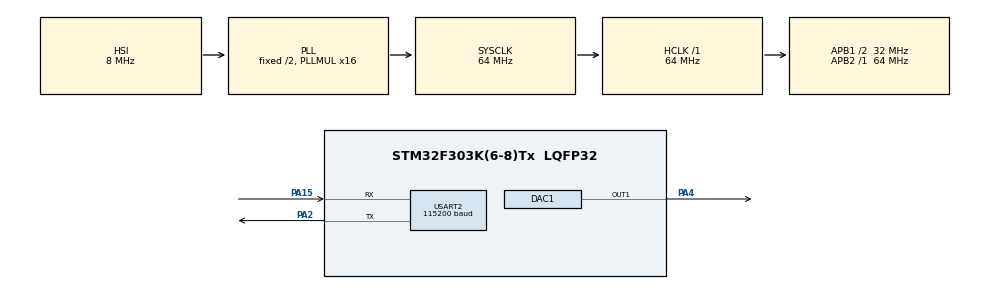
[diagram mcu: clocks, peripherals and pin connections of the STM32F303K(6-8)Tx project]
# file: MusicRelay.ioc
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Mcu.Family=STM32F3
RCC.CortexFreq_Value=64000000
RCC.SYSCLKSourceVirtual=RCC_SYSCLKSOURCE_PLLCLK
NVIC.TIM7_DAC2_IRQn=true\:0\:0\:false\:false\:true\:true\:true
RCC.APB1CLKDivider=RCC_HCLK_DIV2
NVIC.USART2_IRQn=true\:0\:0\:false\:false\:true\:true\:true
USART2.BaudRate=115200
ProjectManager.StackSize=0x400
VP_TIM7_VS_ClockSourceINT.Mode=Enable_Timer
ProjectManager.TargetToolchain=STM32CubeIDE
SH.COMP_DAC11_group.0=DAC1_OUT1,DAC_OUT1
RCC.HCLKFreq_Value=64000000
RCC.APB2TimFreq_Value=64000000
TIM7.Period=160-1
RCC.AHBFreq_Value=64000000
RCC.HSE_VALUE=8000000
TIM7.Prescaler=10-1
board=custom
USART2.VirtualMode-Asynchronous=VM_ASYNC
PA15.Mode=Asynchronous
RCC.PLLMUL=RCC_PLL_MUL16
RCC.APB2Freq_Value=64000000
Mcu.Name=STM32F303K(6-8)Tx
TIM7.TIM_MasterOutputTrigger=TIM_TRGO_UPDATE
PA2.Signal=USART2_TX
DAC1.DAC_Trigger=DAC_TRIGGER_NONE
RCC.SYSCLKFreq_VALUE=64000000
PA4.Signal=COMP_DAC11_group
Mcu.Package=LQFP32
PA15.Signal=USART2_RX
ProjectManager.HeapSize=0x200
RCC.HSI_VALUE=8000000
NVIC.PriorityGroup=NVIC_PRIORITYGROUP_4
RCC.APB1TimFreq_Value=64000000
PA2.Mode=Asynchronous
RCC.APB1Freq_Value=32000000

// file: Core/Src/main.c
/* USER CODE BEGIN Header */
/**
  ******************************************************************************
  * @file           : main.c
  * @brief          : Main program body
  ******************************************************************************
  * @attention
  *
  * <h2><center>&copy; Copyright (c) 2021 STMicroelectronics.
  * All rights reserved.</center></h2>
  *
  * This software component is licensed by ST under BSD 3-Clause license,
  * the "License"; You may not use this file except in compliance with the
  * License. You may obtain a copy of the License at:
  *                        opensource.org/licenses/BSD-3-Clause
  *
  ******************************************************************************
  */
/* USER CODE END Header */
#include "main.h"

/* USER CODE BEGIN Includes */
#include <math.h>
#include <stdlib.h>
#define Num 256
/* USER CODE END Includes */

DAC_HandleTypeDef hdac1;

TIM_HandleTypeDef htim7;

UART_HandleTypeDef huart2;

/* USER CODE BEGIN PV */
char dataLength[8];
char data[255];
char length[10];
uint8_t uartCnt = 0;
uint64_t dataLen;
uint16_t notes[10] = {0};
double buffer[10] = {0};
double tmp[10] = {0};
double sin_table[Num] = {0};

const double timer_clock = 64e6;
const uint16_t timer_PSC = 10 - 1;
const uint16_t timer_ARR = 160 - 1;
uint8_t arrayLen = 0;
double sampling_rate = timer_clock / (timer_PSC+1)/ (timer_ARR+1);

const double sin_offset = 2048;
const double sin_mag = 1800;

const double pi = 3.1415926535897932384626433832795;
/* USER CODE END PV */

void SystemClock_Config(void);
static void MX_GPIO_Init(void);
static void MX_TIM7_Init(void);
static void MX_USART2_UART_Init(void);
static void MX_DAC1_Init(void);
/* USER CODE BEGIN PFP */
float NoteConvert(uint16_t noteNum);
void SortArray(void);
/* USER CODE END PFP */

int main(void)
{

  /* MCU Configuration--------------------------------------------------------*/

  /* Reset of all peripherals, Initializes the Flash interface and the Systick. */
  HAL_Init();

  /* Configure the system clock */
  SystemClock_Config();

  /* Initialize all configured peripherals */
  MX_GPIO_Init();
  MX_TIM7_Init();
  MX_USART2_UART_Init();
  MX_DAC1_Init();
  /* USER CODE BEGIN 2 */
  for(uint16_t i = 0; i < Num; i++){
      sin_table[i] = sin((double)i / Num * 2.0 * pi);
  }

  HAL_UART_Receive_IT(&huart2, (uint8_t *)dataLength, 8);
  HAL_TIM_Base_Start_IT(&htim7);
  HAL_DAC_Start(&hdac1, DAC_CHANNEL_1);
  /* USER CODE END 2 */

  /* Infinite loop */
  while (1)
  {

  }
}

void SystemClock_Config(void)
{
  RCC_OscInitTypeDef RCC_OscInitStruct = {0};
  RCC_ClkInitTypeDef RCC_ClkInitStruct = {0};

  /** Initializes the RCC Oscillators according to the specified parameters
  * in the RCC_OscInitTypeDef structure.
  */
  RCC_OscInitStruct.OscillatorType = RCC_OSCILLATORTYPE_HSI;
  RCC_OscInitStruct.HSIState = RCC_HSI_ON;
  RCC_OscInitStruct.HSICalibrationValue = RCC_HSICALIBRATION_DEFAULT;
  RCC_OscInitStruct.PLL.PLLState = RCC_PLL_ON;
  RCC_OscInitStruct.PLL.PLLSource = RCC_PLLSOURCE_HSI;
  RCC_OscInitStruct.PLL.PLLMUL = RCC_PLL_MUL16;
  if (HAL_RCC_OscConfig(&RCC_OscInitStruct) != HAL_OK)
  {
    Error_Handler();
  }
  /** Initializes the CPU, AHB and APB buses clocks
  */
  RCC_ClkInitStruct.ClockType = RCC_CLOCKTYPE_HCLK|RCC_CLOCKTYPE_SYSCLK
                              |RCC_CLOCKTYPE_PCLK1|RCC_CLOCKTYPE_PCLK2;
  RCC_ClkInitStruct.SYSCLKSource = RCC_SYSCLKSOURCE_PLLCLK;
  RCC_ClkInitStruct.AHBCLKDivider = RCC_SYSCLK_DIV1;
  RCC_ClkInitStruct.APB1CLKDivider = RCC_HCLK_DIV2;
  RCC_ClkInitStruct.APB2CLKDivider = RCC_HCLK_DIV1;

  if (HAL_RCC_ClockConfig(&RCC_ClkInitStruct, FLASH_LATENCY_2) != HAL_OK)
  {
    Error_Handler();
  }
}

static void MX_DAC1_Init(void)
{

  DAC_ChannelConfTypeDef sConfig = {0};

  /** DAC Initialization
  */
  hdac1.Instance = DAC1;
  if (HAL_DAC_Init(&hdac1) != HAL_OK)
  {
    Error_Handler();
  }
  /** DAC channel OUT1 config
  */
  sConfig.DAC_Trigger = DAC_TRIGGER_NONE;
  sConfig.DAC_OutputBuffer = DAC_OUTPUTBUFFER_ENABLE;
  if (HAL_DAC_ConfigChannel(&hdac1, &sConfig, DAC_CHANNEL_1) != HAL_OK)
  {
    Error_Handler();
  }

}

static void MX_TIM7_Init(void)
{

  TIM_MasterConfigTypeDef sMasterConfig = {0};

  htim7.Instance = TIM7;
  htim7.Init.Prescaler = 10-1;
  htim7.Init.CounterMode = TIM_COUNTERMODE_UP;
  htim7.Init.Period = 160-1;
  htim7.Init.AutoReloadPreload = TIM_AUTORELOAD_PRELOAD_DISABLE;
  if (HAL_TIM_Base_Init(&htim7) != HAL_OK)
  {
    Error_Handler();
  }
  sMasterConfig.MasterOutputTrigger = TIM_TRGO_UPDATE;
  sMasterConfig.MasterSlaveMode = TIM_MASTERSLAVEMODE_DISABLE;
  if (HAL_TIMEx_MasterConfigSynchronization(&htim7, &sMasterConfig) != HAL_OK)
  {
    Error_Handler();
  }

}

static void MX_USART2_UART_Init(void)
{

  huart2.Instance = USART2;
  huart2.Init.BaudRate = 115200;
  huart2.Init.WordLength = UART_WORDLENGTH_8B;
  huart2.Init.StopBits = UART_STOPBITS_1;
  huart2.Init.Parity = UART_PARITY_NONE;
  huart2.Init.Mode = UART_MODE_TX_RX;
  huart2.Init.HwFlowCtl = UART_HWCONTROL_NONE;
  huart2.Init.OverSampling = UART_OVERSAMPLING_16;
  huart2.Init.OneBitSampling = UART_ONE_BIT_SAMPLE_DISABLE;
  huart2.AdvancedInit.AdvFeatureInit = UART_ADVFEATURE_NO_INIT;
  if (HAL_UART_Init(&huart2) != HAL_OK)
  {
    Error_Handler();
  }

}

static void MX_GPIO_Init(void)
{

  /* GPIO Ports Clock Enable */
  __HAL_RCC_GPIOA_CLK_ENABLE();

}

/* USER CODE BEGIN 4 */

void HAL_UART_RxCpltCallback(UART_HandleTypeDef *huart)
{
	if(uartCnt){
		uint8_t part = 0;
		uint64_t lastIdx = 0;
		for(uint64_t i = 0; i < dataLen; i++){
			uint8_t Idx = i - lastIdx;
			data[i] &= 0x0f;
			if(Idx < 4){
				part |= data[i] << (3 - Idx);
			}else if(Idx < 5){
				if(data[i] == 0){
					lastIdx = i + 1;
					notes[part] = 0;
					buffer[part] = 0;
					part = 0;
				}
			}else if(Idx < 13){
				notes[part] |= data[i] << (12 - Idx);
			}else{
				notes[part] = (uint16_t)NoteConvert(notes[part]);
				buffer[part] = (double)notes[part] * Num / sampling_rate;
				lastIdx = i;
				part = 0;
			}
			if(i == dataLen - 1){
				notes[part] = (uint16_t)NoteConvert(notes[part]);
				buffer[part] = (double)notes[part] * Num / sampling_rate;
				if(data[i] == 0){
					lastIdx = i + 1;
					notes[part] = 0;
					buffer[part] = 0;
					part = 0;
				}
			}
		}
		SortArray();
		uartCnt = 0;
		HAL_UART_Receive_IT(&huart2, (uint8_t *)dataLength, 8);
		return;
	}
	dataLen = 0;
	for(uint8_t i = 0; i < 8; i++){
		dataLength[i] &= 0x0f;
		dataLen |= dataLength[i] << (7 - i);
	}
	HAL_UART_Receive_IT(&huart2, (uint8_t *)data, dataLen);
	uartCnt++;
}

float NoteConvert(uint16_t noteNum){
	int64_t tmp = noteNum - 69;
	double exp = (double)tmp / 12.0;
	double freq = 440 * pow(2.0, exp);
	return (float)freq;
}
void SortArray(){
	for(uint8_t i = 0; i < 10; i++){
		if(i<9){
			for(uint8_t j = i + 1; j < 10; ++j){
				if(buffer[i] < buffer[j]){
					double tmp1 = buffer[i];
					int32_t tmp2 = notes[i];
					buffer[i] = buffer[j];
					notes[i] = notes[j];
					buffer[j] = tmp1;
					notes[j] = tmp2;
				}
			}
		}
		if(buffer[9 - i] == 0){
			arrayLen = 9 - i;
		}
	}
}
void HAL_TIM_PeriodElapsedCallback(TIM_HandleTypeDef *htim){
	if(htim == &htim7){
		double sum = 0;
		for(uint8_t i = 0; i < arrayLen; i++){
			tmp[i] += buffer[i];
			if(tmp[i] > Num) tmp[i] -= Num;
			sum += sin_table[(int)tmp[i]];
		}
		double freq = sin_mag * sum / arrayLen + sin_offset;
		HAL_DAC_SetValue(&hdac1, DAC_CHANNEL_1, DAC_ALIGN_12B_R, (uint16_t)freq);
	}
}
/* USER CODE END 4 */

void Error_Handler(void)
{
  __disable_irq();
  while (1)
  {
  }
}

/************************ (C) COPYRIGHT STMicroelectronics *****END OF FILE****/
